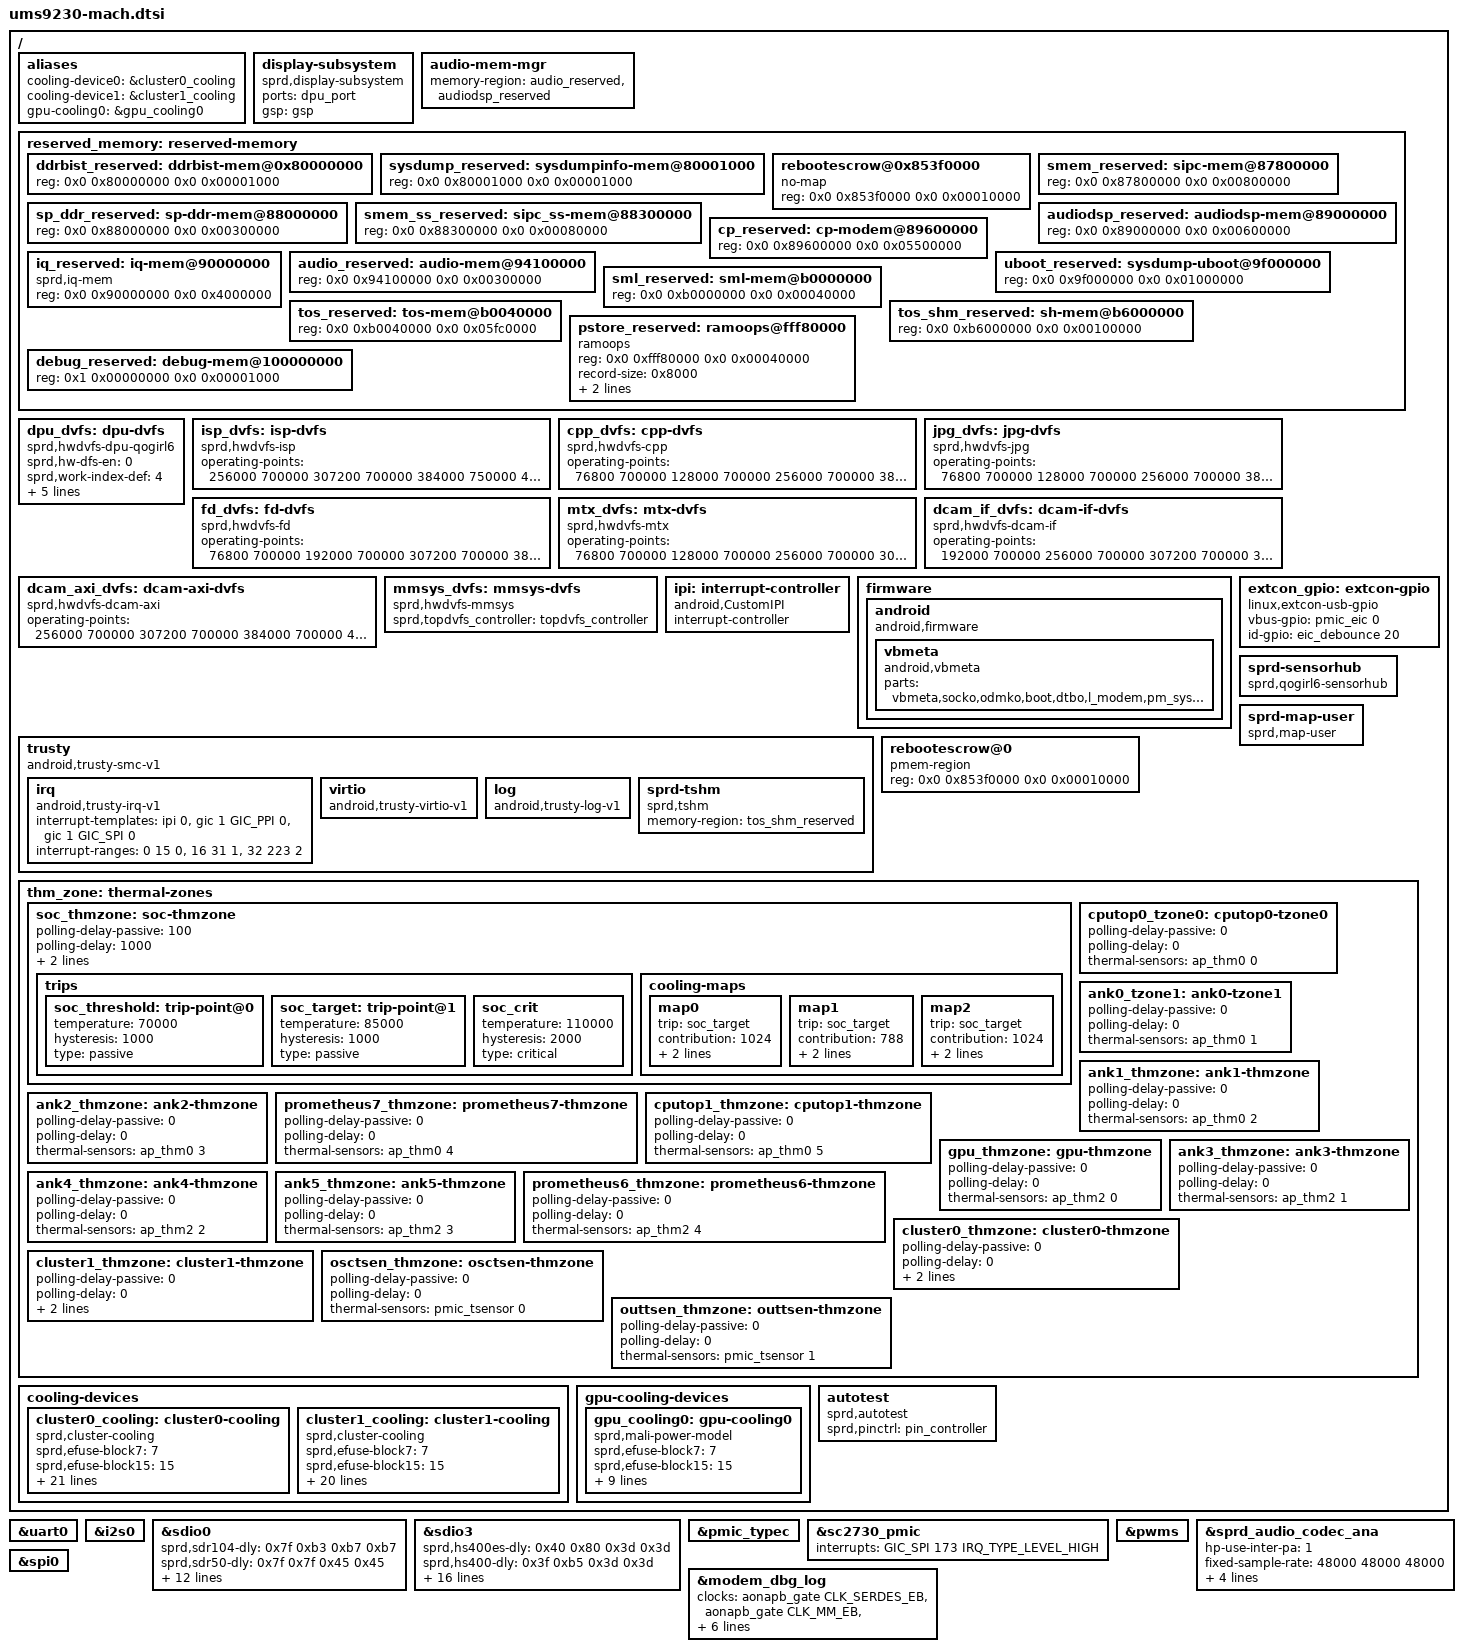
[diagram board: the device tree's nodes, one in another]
/*
 * Spreadtrum Qogirl6 board common DTS file
 *
 * Copyright (C) 2020, Spreadtrum Communications Inc.
 *
 * This file is licensed under a dual GPLv2 or X11 license.
 */

#include <dt-bindings/thermal/thermal.h>

/{
	aliases {
		cooling-device0 = &cluster0_cooling;
		cooling-device1 = &cluster1_cooling;
		gpu-cooling0 = &gpu_cooling0;
	};

	display-subsystem {
		compatible = "sprd,display-subsystem";
		ports = <&dpu_port>;
		gsp = <&gsp>;
	};

	audio-mem-mgr {
		memory-region = <&audio_reserved &audiodsp_reserved>;
	};

	reserved_memory: reserved-memory {
		#address-cells = <2>;
		#size-cells = <2>;
		ranges;

		ddrbist_reserved: ddrbist-mem@0x80000000 {
			reg = <0x0 0x80000000 0x0 0x00001000>;
		};

		sysdump_reserved: sysdumpinfo-mem@80001000 {
			reg = <0x0 0x80001000 0x0 0x00001000>;
		};

		rebootescrow@0x853f0000 {
			no-map;
			reg = <0x0 0x853f0000 0x0 0x00010000>; /* 64K */
		};

		/* must be 64M aligned */
		smem_reserved: sipc-mem@87800000{
			reg = <0x0 0x87800000 0x0 0x00800000>;
		};

		sp_ddr_reserved: sp-ddr-mem@88000000 {
			reg = <0x0 0x88000000 0x0 0x00300000>;
		};

		smem_ss_reserved: sipc_ss-mem@88300000{
			reg = <0x0 0x88300000 0x0 0x00080000>;
		};

		audiodsp_reserved: audiodsp-mem@89000000 {
			reg = <0x0 0x89000000 0x0 0x00600000>;
		};

		cp_reserved: cp-modem@89600000 {
			reg = <0x0 0x89600000 0x0 0x05500000>;
		};

		/* Only used for iq, will be removed in normal mode by uboot */
		iq_reserved: iq-mem@90000000{
			compatible = "sprd,iq-mem";
			reg = <0x0 0x90000000 0x0 0x4000000>;
		};

		audio_reserved: audio-mem@94100000 {
			reg = <0x0 0x94100000 0x0 0x00300000>;
		};

		uboot_reserved: sysdump-uboot@9f000000 {
			reg = <0x0 0x9f000000 0x0 0x01000000>;
		};

		sml_reserved: sml-mem@b0000000 {
		/* the reg valus may be not accurate,
		   they have been fixed in uboot !!! */
			reg = <0x0 0xb0000000 0x0 0x00040000>;
		};

		tos_reserved: tos-mem@b0040000 {
		/* the reg valus may be not accurate,
		   they have been fixed in uboot !!! */
			reg = <0x0 0xb0040000 0x0 0x05fc0000>;
		};

		tos_shm_reserved: sh-mem@b6000000{
			reg = <0x0 0xb6000000 0x0 0x00100000>;
		};

		pstore_reserved: ramoops@fff80000 {
			compatible = "ramoops";
			reg = <0x0 0xfff80000 0x0 0x00040000>;
			record-size = <0x8000>;
			console-size = <0x8000>;
			pmsg-size = <0x8000>;
		};

		debug_reserved: debug-mem@100000000 {
			reg = <0x1 0x00000000 0x0 0x00001000>;
		};
	};

	dpu_dvfs: dpu-dvfs {
		compatible = "sprd,hwdvfs-dpu-qogirl6";
		sprd,hw-dfs-en = <0>;
		sprd,work-index-def = <4>;
		sprd,idle-index-def = <1>;
		sprd,freq-upd-delay-en = <0>;
		sprd,freq-upd-hdsk-en = <1>;

		operating-points = <
				/* kHz    uV */
			153600    700000
			192000    700000
			256000    700000
			307200    700000
			384000    750000
			>;
	};

	isp_dvfs: isp-dvfs {
		compatible = "sprd,hwdvfs-isp";
		operating-points = <
			/* kHz    uV */
			256000    700000
			307200    700000
			384000    750000
			468000    750000
			512000    800000
			>;
	};

	cpp_dvfs: cpp-dvfs {
		compatible = "sprd,hwdvfs-cpp";
		operating-points = <
			/* kHz    uV */
			76800     700000
			128000    700000
			256000    700000
			384000    750000
			>;
	};

	jpg_dvfs: jpg-dvfs {
		compatible = "sprd,hwdvfs-jpg";
		operating-points = <
			/* kHz    uV */
			76800     700000
			128000    700000
			256000    700000
			384000    750000
			>;
	};

	fd_dvfs: fd-dvfs {
		compatible = "sprd,hwdvfs-fd";
		operating-points = <
			/* kHz    uV */
			76800     700000
			192000    700000
			307200    700000
			384000    750000
			>;
	};

	mtx_dvfs: mtx-dvfs {
		compatible = "sprd,hwdvfs-mtx";
		operating-points = <
			/* kHz    uV */
			76800     700000
			128000    700000
			256000    700000
			307200    700000
			384000    750000
			468000    750000
			512000    800000
			>;
	};

	dcam_if_dvfs: dcam-if-dvfs {
		compatible = "sprd,hwdvfs-dcam-if";
		operating-points = <
			/* kHz    uV */
			192000    700000
			256000    700000
			307200    700000
			384000    700000
			468000    750000
			>;
	};

	dcam_axi_dvfs: dcam-axi-dvfs {
		compatible = "sprd,hwdvfs-dcam-axi";
		operating-points = <
			/* kHz    uV */
			256000    700000
			307200    700000
			384000    700000
			468000    750000
			>;
	};

	mmsys_dvfs: mmsys-dvfs {
			compatible = "sprd,hwdvfs-mmsys";
			sprd,topdvfs_controller = <&topdvfs_controller>;
	};

	ipi: interrupt-controller {
		compatible = "android,CustomIPI";
		#interrupt-cells = <1>;
		interrupt-controller;
	};

	firmware {
		android {
			compatible = "android,firmware";
			vbmeta: vbmeta {
				compatible = "android,vbmeta";
				parts = "vbmeta,socko,odmko,boot,dtbo,l_modem,pm_sys,l_ldsp,l_gdsp,l_agdsp";
			};
		};
	};

	trusty {
		compatible = "android,trusty-smc-v1";
		irq {
			compatible = "android,trusty-irq-v1";
			interrupt-templates = <&ipi 0>,
						<&gic 1 GIC_PPI 0>,
						<&gic 1 GIC_SPI 0>;
				interrupt-ranges = < 0  15 0>,
						<16  31 1>,
						<32 223 2>;
		};

		virtio {
			compatible = "android,trusty-virtio-v1";
		};

		log {
			compatible = "android,trusty-log-v1";
		};

		sprd-tshm {
			compatible = "sprd,tshm";
			memory-region = <&tos_shm_reserved>;
		};

	};

	rebootescrow@0 {
		compatible = "pmem-region";
		reg = <0x0 0x853f0000 0x0 0x00010000>;
	};

	extcon_gpio: extcon-gpio {
		compatible = "linux,extcon-usb-gpio";
		vbus-gpio = <&pmic_eic 0 GPIO_ACTIVE_HIGH>;
		/* HS03 code for SR-SL6215-01-186 by gaochao at 20210729 start */
		id-gpio = <&eic_debounce 20 GPIO_ACTIVE_HIGH>;
		/* HS03 code for SR-SL6215-01-186 by gaochao at 20210729 end */
	};

	sprd-sensorhub {
		 compatible = "sprd,qogirl6-sensorhub", "sprd,sensor-hub";
	};

	sprd-map-user {
		compatible = "sprd,map-user";
	};

	thm_zone: thermal-zones {
		soc_thmzone: soc-thmzone {
			polling-delay-passive = <100>;
			polling-delay = <1000>;
			sustainable-power = <4500>;
			thermal-sensors = <&soc_sensor  17>;
			trips {
				soc_threshold: trip-point@0 {
					temperature = <70000>;
					hysteresis = <1000>;
					type = "passive";
				};
				soc_target: trip-point@1 {
					temperature = <85000>;
					hysteresis = <1000>;
					type = "passive";
				};
				soc_crit: soc_crit {
					temperature = <110000>;
					hysteresis = <2000>;
					type = "critical";
				};
			};
			cooling-maps {
				map0 {
					trip = <&soc_target>;
					contribution = <1024>;
					cooling-device =
					<&cluster0_cooling THERMAL_NO_LIMIT \
					THERMAL_NO_LIMIT>;
				};
				map1 {
					trip = <&soc_target>;
					contribution = <788>;
					cooling-device =
					<&cluster1_cooling THERMAL_NO_LIMIT \
					THERMAL_NO_LIMIT>;
				};
				map2 {
					trip = <&soc_target>;
					contribution = <1024>;
					cooling-device =
					<&gpu_cooling0 THERMAL_NO_LIMIT \
					THERMAL_NO_LIMIT>;
				};
			};
		};

		cputop0_tzone0: cputop0-tzone0 {
			polling-delay-passive = <0>;
			polling-delay = <0>;
			thermal-sensors = <&ap_thm0 0>;
		};

		ank0_tzone1: ank0-tzone1 {
			polling-delay-passive = <0>;
			polling-delay = <0>;
			thermal-sensors = <&ap_thm0 1>;
		};

		ank1_thmzone: ank1-thmzone {
			polling-delay-passive = <0>;
			polling-delay = <0>;
			thermal-sensors = <&ap_thm0 2>;
		};

		ank2_thmzone: ank2-thmzone {
			polling-delay-passive = <0>;
			polling-delay = <0>;
			thermal-sensors = <&ap_thm0 3>;
		};

		prometheus7_thmzone: prometheus7-thmzone {
			polling-delay-passive = <0>;
			polling-delay = <0>;
			thermal-sensors = <&ap_thm0 4>;
		};

		cputop1_thmzone: cputop1-thmzone {
			polling-delay-passive = <0>;
			polling-delay = <0>;
			thermal-sensors = <&ap_thm0 5>;
		};

		gpu_thmzone: gpu-thmzone {
			polling-delay-passive = <0>;
			polling-delay = <0>;
			thermal-sensors = <&ap_thm2 0>;
		};

		ank3_thmzone: ank3-thmzone {
			polling-delay-passive = <0>;
			polling-delay = <0>;
			thermal-sensors = <&ap_thm2 1>;
		};

		ank4_thmzone: ank4-thmzone {
			polling-delay-passive = <0>;
			polling-delay = <0>;
			thermal-sensors = <&ap_thm2 2>;
		};

		ank5_thmzone: ank5-thmzone {
			polling-delay-passive = <0>;
			polling-delay = <0>;
			thermal-sensors = <&ap_thm2 3>;
		};

		prometheus6_thmzone: prometheus6-thmzone {
			polling-delay-passive = <0>;
			polling-delay = <0>;
			thermal-sensors = <&ap_thm2 4>;
		};

		cluster0_thmzone: cluster0-thmzone {
			polling-delay-passive = <0>;
			polling-delay = <0>;
			sustainable-power = <2000>;
			thermal-sensors = <&cluster0_sensor  15>;
		};

		cluster1_thmzone: cluster1-thmzone {
			polling-delay-passive = <0>;
			polling-delay = <0>;
			sustainable-power = <2000>;
			thermal-sensors = <&cluster1_sensor  16>;
		};

		osctsen_thmzone: osctsen-thmzone {
			 polling-delay-passive = <0>;
			 polling-delay = <0>;
			 thermal-sensors = <&pmic_tsensor 0>;
		 };

		outtsen_thmzone: outtsen-thmzone {
			 polling-delay-passive = <0>;
			 polling-delay = <0>;
			 thermal-sensors = <&pmic_tsensor 1>;
		 };
	};

	cooling-devices {
		cluster0_cooling: cluster0-cooling {
			compatible = "sprd,cluster-cooling";
			#cooling-cells = <2>; /* min followesd by max */
			sprd,efuse-block7 = <7>;
			sprd,efuse-block15 = <15>;
			/* core_leak =                             */
			/*(LIT_LEAK[4:0]+1) x 2mA x 0.85V x 18.69% */
			sprd,leak-core = <2 85 1869>;
			/* cluster_leak =                           */
			/* (LIT_LEAK[4:0]+1) x 2mA x 0.85V x 25.24% */
			sprd,leak-cluster = <2 85 2524>;
			/*core Tscale = aT^3 + bT^2 + cT +di   */
			sprd,core-temp-scale =
			/* a*10^7   b*10^7      c*10^7     d*10^7 */
			<  15      (-730)      70000    (-120000)>;
			/*core Vscale = eV^3 + fV^2 + gV + h */
			sprd,core-voltage-scale =
			/* e*10^2   f*10^2     g*10^2  h*10^2*/
			<  792     (-1868)      1581      (-406)>;
			/*cluster Tscale = aT^3 + bT^2 + cT +di   */
			sprd,cluster-temp-scale =
			/* a*10^7   b*10^7      c*10^7     d*10^7 */
			<  15      (-728)      70000    (-120000)>;
			/*cluster Vscale = eV^3 + fV^2 + gV + h */
			sprd,cluster-voltage-scale =
			/* e*10^2   f*10^2     g*10^2  h*10^2*/
			<  792     (-1868)      1582      (-406)>;
			sprd,efuse-switch = <0>;
			sprd,hotplug-period = <10>;
			sprd,min-cpufreq = <614400>;
			sprd,min-cpunum = <1>;
			sprd,core-base = <4075>;
			sprd,cluster-base = <3891>;
			sprd,dynamic-core =
			/*Pdynperghz*10    Freq     Vbase  */
			< 889           1000     1000>;
			sprd,dynamic-cluster =
			/*Pdynperghz*10    Freq     Vbase  */
			< 322           1000     1000>;
			/* HS03 code(Unisoc Patch) for SL6215SDEV-358 by lina at 20220509 start */
			sprd,sensor-names = "ank0-tzone1",
			"ank1-thmzone",
			"ank2-thmzone",
			"ank3-thmzone",
			"ank4-thmzone",
			"ank5-thmzone";
			/* HS03 code(Unisoc Patch) for SL6215SDEV-358 by lina at 20220509 end */
		};

		cluster1_cooling: cluster1-cooling {
			compatible = "sprd,cluster-cooling";
			#cooling-cells = <2>; /* min followed by max */
			sprd,efuse-block7 = <7>;
			sprd,efuse-block15 = <15>;
			/* core_leak =                             */
			/*(LIT_LEAK[4:0]+1) x 2mA x 0.85V x 18.69% */
			sprd,leak-core = <8 85 1984>;
			/* cluster_leak =                           */
			/* (LIT_LEAK[4:0]+1) x 2mA x 0.85V x 25.24% */
			sprd,leak-cluster = <8 85 2064>;
			/*core Tscale = aT^3 + bT^2 + cT +d  */
			sprd,core-temp-scale =
			/* a*10^7   b*10^7	c*10^7	   d*10^7*/
			<  15      (-728)      70000    (-120000)>;
			/* core  Vscale = eV^3 + fV^2 + gV + h */
			sprd,core-voltage-scale =
			/* e*10^2  f*10^2     g*10^2  h*10^2*/
			<  792     (-1868)      1582      (-406)>;
			/*cluster Tscale = aT^3 + bT^2 + cT +di   */
			sprd,cluster-temp-scale =
			/* a*10^7   b*10^7      c*10^7     d*10^7 */
			<  15      (-728)      70000    (-120000)>;
			/*cluster Vscale = eV^3 + fV^2 + gV + h */
			sprd,cluster-voltage-scale =
			/* e*10^2   f*10^2     g*10^2  h*10^2*/
			<  792     (-1868)      1582      (-406)>;
			sprd,efuse-switch = <0>;
			sprd,hotplug-period = <10>;
			sprd,min-cpufreq = <1228800>;
			sprd,min-cpunum = <0>;
			sprd,core-base = <11051>;
			sprd,cluster-base = <3891>;
			sprd,dynamic-core =
			/* Pdynperghz*10    Freq     Vbase */
			<  4209          1000     1000>;
			sprd,dynamic-cluster =
			/* Pdynperghz*10    Freq     Vbase */
			<  322           1000     1000>;
			/* HS03 code(Unisoc Patch) for SL6215SDEV-358 by lina at 20220509 start */
			sprd,sensor-names = "prometheus6-thmzone",
			"prometheus7-thmzone";
			/* HS03 code(Unisoc Patch) for SL6215SDEV-358 by lina at 20220509 end */
		};
	};

	gpu-cooling-devices {
		gpu_cooling0: gpu-cooling0 {
			compatible = "sprd,mali-power-model";
			#cooling-cells = <2>;
			sprd,efuse-block7 = <7>;
			sprd,efuse-block15 = <15>;
			/* core_leak =                             */
			/*(LIT_LEAK[4:0]+1) x 2mA x 0.85V x 18.69% */
			sprd,leak-core = <2 85 1869>;
			/* cluster_leak =                           */
			/* (LIT_LEAK[4:0]+1) x 2mA x 0.85V x 25.24% */
			sprd,leak-cluster = <2 85 2524>;
			/*Tscale = aT^3 + bT^2 + cT +di   */
			sprd,temp-scale =
			/* a*10^7   b*10^7      c*10^7     d*10^7 */
			<  25     (-2204)     131423    (-740872)>;
			/*Vscale = eV^3 + fV^2 + gV + h */
			sprd,voltage-scale =
			/* e*10^2   f*10^2     g*10^2      h*10^2*/
			<  801  (-1712)       1335     (-324)>;
			sprd,hotplug-period = <0>;
			/* core Vbase*10^2*/
			sprd,core-base = <5318>;
			/* cluster Vbase*10^2*/
			sprd,cluster-base = <966>;
			sprd,dynamic-core =
			/*Pdynperghz*10^2    Freq     Vbase  */
			< 7670           850     1000>;
			sprd,dynamic-cluster =
			/*Pdynperghz*10^2    Freq     Vbase  */
			< 6064           850     1000>;
		};
	};

    autotest:autotest{
		compatible = "sprd,autotest";
		sprd,pinctrl = <&pin_controller>;
	};
};

&uart0 {
	status = "okay";
};

&i2s0 {
	status = "okay";
};

&sdio0 {
	sprd,sdr104-dly = <0x7f 0xb3 0xb7 0xb7>;
	sprd,sdr50-dly = <0x7f 0x7f 0x45 0x45>;
	sprd,sdhs-dly = <0x7f 0x8d 0xaf 0xaf>;
	sprd,legacy-dly = <0x7f 0x1a 0x9a 0x9a>;
	vmmc-supply = <&vddsdcore>;
	vqmmc-supply = <&vddsdio>;
	voltage-ranges = <3000 3000>;
	bus-width = <4>;
	sd-uhs-sdr104;
	sd-uhs-sdr50;
	sprd,name = "sdio_sd";
	sprd,sdio-adma;
	no-sdio;
	no-mmc;
	status = "okay";
};

&sdio3 {
	sprd,hs400es-dly = <0x40 0x80 0x3d 0x3d>;
	sprd,hs400-dly = <0x3f 0xb5 0x3d 0x3d>;
	sprd,hs200-dly = <0x7f 0xb5 0xb5 0xb5>;
	sprd,ddr52-dly = <0x3e 0x6a 0x48 0x48>;
	sprd,mmchs-dly = <0x60 0x2e 0x2c 0x2c>;
	vmmc-supply = <&vddemmccore>;
	voltage-ranges = <3000 3000>;
	bus-width = <8>;
	non-removable;
	cap-mmc-hw-reset;
	mmc-hs400-enhanced-strobe;
	mmc-hs400-1_8v;
	mmc-hs200-1_8v;
	mmc-ddr-1_8v;
	sprd,name = "sdio_emmc";
	sprd,sdio-adma;
	no-sdio;
	no-sd;
	status = "okay";
};

&pmic_typec {
	status = "okay";
};

&sc2730_pmic {
	interrupts = <GIC_SPI 173 IRQ_TYPE_LEVEL_HIGH>;
};

&pwms {
	status = "okay";
};

&sprd_audio_codec_ana {
	status = "okay";
	hp-use-inter-pa = <1>;
	fixed-sample-rate = <48000 48000 48000>;
	digital-codec = <&sprd_audio_codec_dig>;
	set-offset = <0x1000>;
	clr-offset = <0x2000>;
	lrdat-sel = <0x1>;
};

&spi0 {
	/*used for fingerprint sensor*/
	status = "okay";
};

&modem_dbg_log{
	status = "okay";
	clock-names = "serdes_eb", "mm_eb", "ana_eb", "dsi_csi_test_eb", "cphy_cfg_eb";
	clocks = <&aonapb_gate CLK_SERDES_EB>, <&aonapb_gate CLK_MM_EB>, <&aonapb_gate CLK_ANA_EB>,
		<&aonapb_gate CLK_DSI_CSI_TEST_EB>, <&aonapb_gate CLK_CPHY_CFG_EN>;
	vddio-supply = <&vddcamio>;
	mipi-switch-en-gpios = <&ap_gpio 55 GPIO_ACTIVE_HIGH>;
	mipi-switch-mode-gpios = <&ap_gpio 8 GPIO_ACTIVE_HIGH>;
};

/* HS03 code for SL6215SDEV-358 by lina at 20220509 start */
#include "HS03/hs03_thermal.dtsi"
/* HS03 code for SL6215SDEV-358 by lina at 20220509 end */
